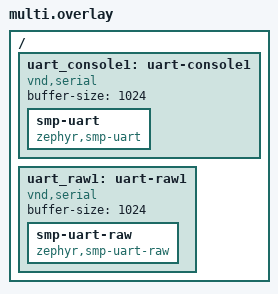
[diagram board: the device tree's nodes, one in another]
/*
 * SPDX-FileCopyrightText: Copyright The Zephyr Project Contributors
 *
 * SPDX-License-Identifier: Apache-2.0
 */

/ {
	uart_console1: uart-console1 {
		compatible = "vnd,serial";
		buffer-size = <1024>;
		status = "okay";

		smp-uart {
			compatible = "zephyr,smp-uart";
		};
	};

	uart_raw1: uart-raw1 {
		compatible = "vnd,serial";
		buffer-size = <1024>;
		status = "okay";

		smp-uart-raw {
			compatible = "zephyr,smp-uart-raw";
		};
	};
};
